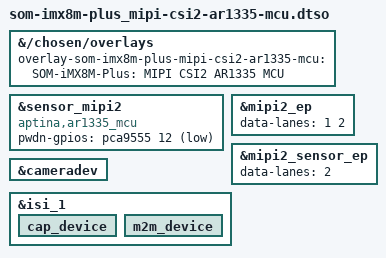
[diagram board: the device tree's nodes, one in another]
#include "overlay.h"

&{/chosen/overlays} {
	overlay-som-imx8m-plus-mipi-csi2-ar1335-mcu = "SOM-iMX8M-Plus: MIPI CSI2 AR1335 MCU";
};

#include "som-imx8m-plus_mipi-csi2.dtsi"

&sensor_mipi2 {
	compatible = "aptina,ar1335_mcu", "ar1335_mcu";
	pwdn-gpios = <&pca9555 12 GPIO_ACTIVE_LOW>;
};

&mipi2_ep {
	data-lanes = <1 2>;
};

&mipi2_sensor_ep {
	data-lanes = <2>;
};

&cameradev {
	status = "okay";
};

&isi_1 {
	status = "okay";

	cap_device {
		status = "okay";
	};

	m2m_device {
		status = "okay";
	};
};
